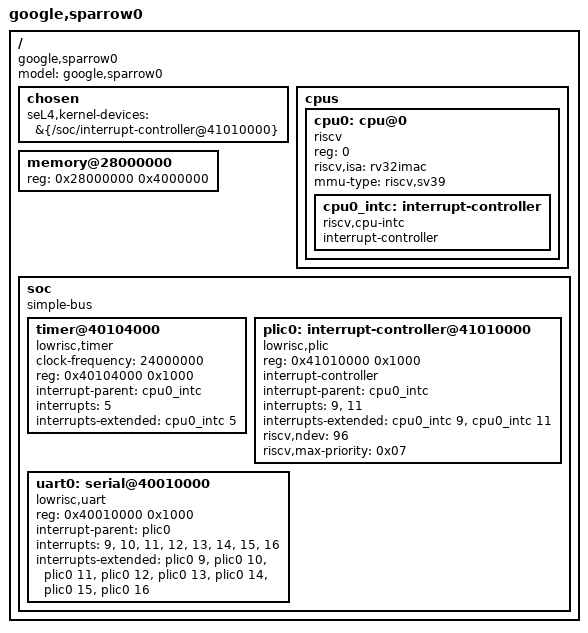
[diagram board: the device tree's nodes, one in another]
// DeviceTree for the Sparrow SMC

/dts-v1/;

/ {
  #address-cells = <1>;
  #size-cells = <1>;
  compatible = "google,sparrow0";
  model = "google,sparrow0";

  chosen {
    // seL4 requires including devices that it should memory map here.
    seL4,kernel-devices =
        &{/soc/interrupt-controller@41010000};
    // (The timer is deliberately not here, since having more than one 4MB
    // range containing kernel devices causes an overflow beyond the end of
    // virtual address space when mapping them.)
  };

  cpus {
    #address-cells = <1>;
    #size-cells = <0>;
    cpu0: cpu@0 {
      device_type = "cpu";
      reg = <0>;
      compatible = "riscv";
      riscv,isa = "rv32imac";
      mmu-type = "riscv,sv39";
      status = "okay";

      cpu0_intc: interrupt-controller {
        #interrupt-cells = <1>;
        compatible = "riscv,cpu-intc";
        interrupt-controller;
        phandle = <0x0f>;
      };
    };
  };

  memory@28000000 {
    #address-cells = <1>;
    #size-cells = <1>;
    device_type = "memory";
    // TODO(b/197745020): Change the size to 0x400000 after the system is made
    // small enough to fit.
    reg = <0x28000000 0x4000000>;
  };

  soc {
    #address-cells = <1>;
    #size-cells = <1>;
    compatible = "simple-bus";
    ranges;
    timer@40104000 {
      compatible = "lowrisc,timer";
      clock-frequency = < 24000000 >;
      reg = < 0x40104000 0x1000 >;
      interrupt-parent = <&cpu0_intc>;
      interrupts = <5>;
      interrupts-extended = <&cpu0_intc 5>;
    };
    plic0: interrupt-controller@41010000 {
      #interrupt-cells = <1>;
      compatible = "lowrisc,plic";
      reg = <0x41010000 0x1000>;
      interrupt-controller;
      interrupt-parent = <&cpu0_intc>;
      interrupts = <9>, <11>;
      interrupts-extended = <&cpu0_intc 9>, <&cpu0_intc 11>;
      riscv,ndev = <96>;
      riscv,max-priority = <0x07>;
    };
    uart0: serial@40010000 {
      compatible = "lowrisc,uart";
      reg = <0x40010000 0x1000>;
      interrupt-parent = <&plic0>;
      interrupts = <9>, <10>, <11>, <12>, <13>, <14>, <15>, <16>;
      interrupts-extended = <&plic0 9>, <&plic0 10>, <&plic0 11>,
          <&plic0 12>, <&plic0 13>, <&plic0 14>, <&plic0 15>, <&plic0 16>;
    };
  };
};
